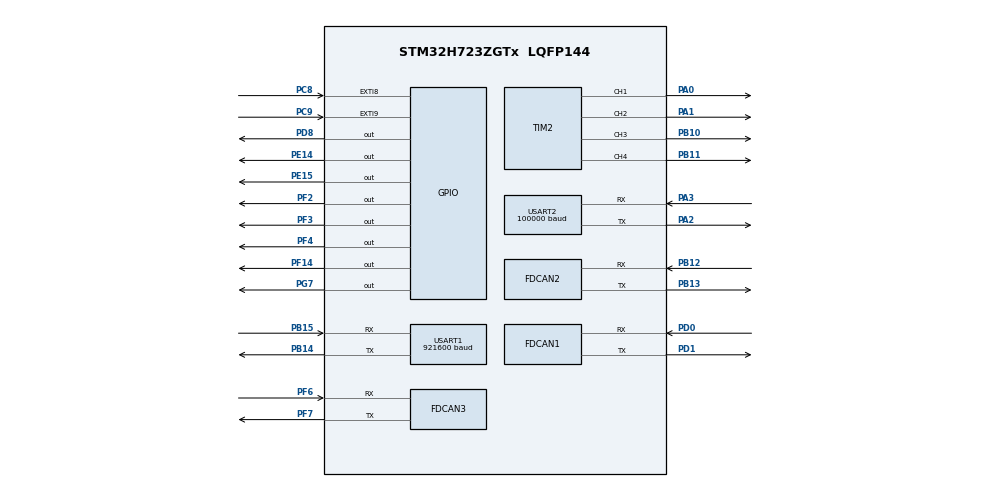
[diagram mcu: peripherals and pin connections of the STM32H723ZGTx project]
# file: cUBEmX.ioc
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CORTEX_M7.CPU_DCache=Disabled
CORTEX_M7.CPU_ICache=Disabled
CORTEX_M7.MPU_Control=__NULL
CORTEX_M7.default_mode_Activation=0
Dma.Request0=USART1_RX
Dma.Request1=USART1_TX
Dma.Request2=USART2_RX
Dma.USART1_RX.0.Direction=DMA_PERIPH_TO_MEMORY
Dma.USART1_RX.0.EventEnable=DISABLE
Dma.USART1_RX.0.FIFOMode=DMA_FIFOMODE_DISABLE
Dma.USART1_RX.0.Instance=DMA1_Stream1
Dma.USART1_RX.0.MemDataAlignment=DMA_MDATAALIGN_BYTE
Dma.USART1_RX.0.MemInc=DMA_MINC_ENABLE
Dma.USART1_RX.0.Mode=DMA_NORMAL
Dma.USART1_RX.0.PeriphDataAlignment=DMA_PDATAALIGN_BYTE
Dma.USART1_RX.0.PeriphInc=DMA_PINC_DISABLE
Dma.USART1_RX.0.Polarity=HAL_DMAMUX_REQ_GEN_RISING
Dma.USART1_RX.0.Priority=DMA_PRIORITY_LOW
Dma.USART1_RX.0.RequestNumber=1
Dma.USART1_RX.0.SignalID=NONE
Dma.USART1_RX.0.SyncEnable=DISABLE
Dma.USART1_RX.0.SyncPolarity=HAL_DMAMUX_SYNC_NO_EVENT
Dma.USART1_RX.0.SyncRequestNumber=1
Dma.USART1_RX.0.SyncSignalID=NONE
Dma.USART1_TX.1.Direction=DMA_MEMORY_TO_PERIPH
Dma.USART1_TX.1.EventEnable=DISABLE
Dma.USART1_TX.1.FIFOMode=DMA_FIFOMODE_DISABLE
Dma.USART1_TX.1.Instance=DMA1_Stream2
Dma.USART1_TX.1.MemDataAlignment=DMA_MDATAALIGN_BYTE
Dma.USART1_TX.1.MemInc=DMA_MINC_ENABLE
Dma.USART1_TX.1.Mode=DMA_NORMAL
Dma.USART1_TX.1.PeriphDataAlignment=DMA_PDATAALIGN_BYTE
Dma.USART1_TX.1.PeriphInc=DMA_PINC_DISABLE
Dma.USART1_TX.1.Polarity=HAL_DMAMUX_REQ_GEN_RISING
Dma.USART1_TX.1.Priority=DMA_PRIORITY_LOW
Dma.USART1_TX.1.RequestNumber=1
Dma.USART1_TX.1.SignalID=NONE
Dma.USART1_TX.1.SyncEnable=DISABLE
Dma.USART1_TX.1.SyncPolarity=HAL_DMAMUX_SYNC_NO_EVENT
Dma.USART1_TX.1.SyncRequestNumber=1
Dma.USART1_TX.1.SyncSignalID=NONE
Dma.USART2_RX.2.Direction=DMA_PERIPH_TO_MEMORY
Dma.USART2_RX.2.EventEnable=DISABLE
Dma.USART2_RX.2.FIFOMode=DMA_FIFOMODE_DISABLE
Dma.USART2_RX.2.Instance=DMA1_Stream0
Dma.USART2_RX.2.MemDataAlignment=DMA_MDATAALIGN_BYTE
Dma.USART2_RX.2.MemInc=DMA_MINC_ENABLE
Dma.USART2_RX.2.Mode=DMA_NORMAL
Dma.USART2_RX.2.PeriphDataAlignment=DMA_PDATAALIGN_BYTE
Dma.USART2_RX.2.PeriphInc=DMA_PINC_DISABLE
Dma.USART2_RX.2.Polarity=HAL_DMAMUX_REQ_GEN_RISING
Dma.USART2_RX.2.Priority=DMA_PRIORITY_MEDIUM
Dma.USART2_RX.2.RequestNumber=1
Dma.USART2_RX.2.SignalID=NONE
Dma.USART2_RX.2.SyncEnable=DISABLE
Dma.USART2_RX.2.SyncPolarity=HAL_DMAMUX_SYNC_NO_EVENT
Dma.USART2_RX.2.SyncRequestNumber=1
Dma.USART2_RX.2.SyncSignalID=NONE
FDCAN1.AutoRetransmission=ENABLE
FDCAN1.CalculateBaudRateNominal=1000000
FDCAN1.CalculateTimeBitNominal=1000
FDCAN1.CalculateTimeQuantumNominal=200.0
FDCAN1.ClockCalibrationCCU=DISABLE
FDCAN1.DataPrescaler=5
FDCAN1.DataTimeSeg1=2
FDCAN1.DataTimeSeg2=2
FDCAN1.NominalPrescaler=5
FDCAN1.RxFifo0ElmtsNbr=3
FDCAN1.StdFiltersNbr=1
FDCAN1.TxFifoQueueElmtsNbr=8
FDCAN1.TxFifoQueueMode=FDCAN_TX_FIFO_OPERATION
FDCAN2.AutoRetransmission=ENABLE
FDCAN2.CalculateBaudRateNominal=1000000
FDCAN2.CalculateTimeBitNominal=1000
FDCAN2.CalculateTimeQuantumNominal=200.0
FDCAN2.DataPrescaler=5
FDCAN2.DataTimeSeg1=2
FDCAN2.DataTimeSeg2=2
FDCAN2.MessageRAMOffset=796
FDCAN2.NominalPrescaler=5
FDCAN2.RxFifo0ElmtsNbr=3
FDCAN2.StdFiltersNbr=1
FDCAN2.TxFifoQueueElmtsNbr=8
FDCAN3.AutoRetransmission=ENABLE
FDCAN3.CalculateBaudRateNominal=1000000
FDCAN3.CalculateTimeBitNominal=1000
FDCAN3.CalculateTimeQuantumNominal=200.0
FDCAN3.DataPrescaler=5
FDCAN3.DataTimeSeg1=2
FDCAN3.DataTimeSeg2=2
FDCAN3.MessageRAMOffset=1592
FDCAN3.NominalPrescaler=5
FDCAN3.RxFifo0ElmtsNbr=3
FDCAN3.StdFiltersNbr=1
FDCAN3.TxFifoQueueElmtsNbr=8
Mcu.Family=STM32H7
Mcu.Name=STM32H723ZGTx
Mcu.Package=LQFP144
NVIC.DMA1_Stream0_IRQn=true\:0\:0\:false\:false\:true\:false\:true\:true
NVIC.DMA1_Stream1_IRQn=true\:0\:0\:false\:false\:true\:false\:true\:true
NVIC.DMA1_Stream2_IRQn=true\:0\:0\:false\:false\:true\:false\:true\:true
NVIC.FDCAN1_IT0_IRQn=true\:0\:0\:false\:false\:true\:true\:true\:true
NVIC.FDCAN2_IT0_IRQn=true\:0\:0\:false\:false\:true\:true\:true\:true
NVIC.FDCAN3_IT0_IRQn=true\:0\:0\:false\:false\:true\:true\:true\:true
NVIC.PriorityGroup=NVIC_PRIORITYGROUP_4
NVIC.USART1_IRQn=true\:0\:0\:false\:false\:true\:true\:true\:true
NVIC.USART2_IRQn=true\:0\:0\:false\:false\:true\:true\:true\:true
PA0.GPIO_Speed=GPIO_SPEED_FREQ_VERY_HIGH
PA0.Signal=S_TIM2_CH1_ETR
PA1.GPIO_Speed=GPIO_SPEED_FREQ_VERY_HIGH
PA1.Signal=S_TIM2_CH2
PA2.GPIO_Speed=GPIO_SPEED_FREQ_VERY_HIGH
PA2.Mode=Asynchronous
PA2.Signal=USART2_TX
PA3.GPIO_Speed=GPIO_SPEED_FREQ_VERY_HIGH
PA3.Mode=Asynchronous
PA3.Signal=USART2_RX
PB10.GPIO_Speed=GPIO_SPEED_FREQ_VERY_HIGH
PB10.Signal=S_TIM2_CH3
PB11.GPIO_Speed=GPIO_SPEED_FREQ_VERY_HIGH
PB11.Signal=S_TIM2_CH4
PB12.Mode=FDCAN_Activate
PB12.Signal=FDCAN2_RX
PB13.Mode=FDCAN_Activate
PB13.Signal=FDCAN2_TX
PB14.GPIO_Speed=GPIO_SPEED_FREQ_VERY_HIGH
PB14.Mode=Asynchronous
PB14.Signal=USART1_TX
PB15.GPIO_Speed=GPIO_SPEED_FREQ_VERY_HIGH
PB15.Mode=Asynchronous
PB15.Signal=USART1_RX
PC14-OSC32_IN.Mode=LSE-External-Oscillator
PC14-OSC32_IN.Signal=RCC_OSC32_IN
PC15-OSC32_OUT.Mode=LSE-External-Oscillator
PC15-OSC32_OUT.Signal=RCC_OSC32_OUT
PC8.GPIO_ModeDefaultEXTI=GPIO_MODE_IT_FALLING
PC8.GPIO_PuPd=GPIO_PULLUP
PC8.Signal=GPXTI8
PC9.GPIO_ModeDefaultEXTI=GPIO_MODE_IT_FALLING
PC9.GPIO_PuPd=GPIO_PULLUP
PC9.Signal=GPXTI9
PD0.GPIO_Speed=GPIO_SPEED_FREQ_VERY_HIGH
PD0.Mode=FDCAN_Activate
PD0.Signal=FDCAN1_RX
PD1.GPIO_Speed=GPIO_SPEED_FREQ_VERY_HIGH
PD1.Mode=FDCAN_Activate
PD1.Signal=FDCAN1_TX
PD8.GPIO_Speed=GPIO_SPEED_FREQ_VERY_HIGH
PD8.PinState=GPIO_PIN_RESET
PD8.Signal=GPIO_Output
PE14.GPIO_Speed=GPIO_SPEED_FREQ_VERY_HIGH
PE14.Signal=GPIO_Output
PE15.GPIO_Speed=GPIO_SPEED_FREQ_VERY_HIGH
PE15.Signal=GPIO_Output
PF14.GPIO_Speed=GPIO_SPEED_FREQ_VERY_HIGH
PF14.Signal=GPIO_Output
PF2.GPIO_Speed=GPIO_SPEED_FREQ_VERY_HIGH
PF2.Signal=GPIO_Output
PF3.GPIO_Speed=GPIO_SPEED_FREQ_VERY_HIGH
PF3.Signal=GPIO_Output
PF4.GPIO_Speed=GPIO_SPEED_FREQ_VERY_HIGH
PF4.Signal=GPIO_Output
PF6.Mode=FDCAN_Activate
PF6.Signal=FDCAN3_RX
PF7.Mode=FDCAN_Activate
PF7.Signal=FDCAN3_TX
PG7.GPIO_Speed=GPIO_SPEED_FREQ_VERY_HIGH
PG7.Signal=GPIO_Output
PH0-OSC_IN.Mode=HSE-External-Oscillator
PH0-OSC_IN.Signal=RCC_OSC_IN
PH1-OSC_OUT.Mode=HSE-External-Oscillator
PH1-OSC_OUT.Signal=RCC_OSC_OUT
ProjectManager.HeapSize=0x200
ProjectManager.StackSize=0x400
ProjectManager.TargetToolchain=MDK-ARM V5.32
RCC.ADCFreq_Value=129000000
RCC.APB1Freq_Value=120000000
RCC.APB2Freq_Value=120000000
RCC.APB3Freq_Value=120000000
RCC.APB4Freq_Value=120000000
RCC.CortexFreq_Value=480000000
RCC.D1PPRE=RCC_APB3_DIV2
RCC.D2PPRE1=RCC_APB1_DIV2
RCC.D2PPRE2=RCC_APB2_DIV2
RCC.D3PPRE=RCC_APB4_DIV2
RCC.DIVM1=4
RCC.DIVN1=30
RCC.DIVP1=1
RCC.DIVQ1=4
RCC.FDCANCLockSelection=RCC_FDCANCLKSOURCE_HSE
RCC.HCLKFreq_Value=240000000
RCC.HPRE=RCC_HCLK_DIV2
RCC.PLL2FRACN=0
RCC.PLL3FRACN=0
RCC.PLLFRACN=0
RCC.SYSCLKFreq_VALUE=480000000
RCC.SYSCLKSource=RCC_SYSCLKSOURCE_PLLCLK
RCC.USBFreq_Value=120000000
SH.S_TIM2_CH1_ETR.0=TIM2_CH1,PWM Generation1 CH1
SH.S_TIM2_CH2.0=TIM2_CH2,PWM Generation2 CH2
SH.S_TIM2_CH3.0=TIM2_CH3,PWM Generation3 CH3
SH.S_TIM2_CH4.0=TIM2_CH4,PWM Generation4 CH4
TIM2.Channel-PWM\ Generation1\ CH1=TIM_CHANNEL_1
TIM2.Channel-PWM\ Generation2\ CH2=TIM_CHANNEL_2
TIM2.Channel-PWM\ Generation3\ CH3=TIM_CHANNEL_3
TIM2.Channel-PWM\ Generation4\ CH4=TIM_CHANNEL_4
USART1.BaudRate=921600
USART1.VirtualMode-Asynchronous=VM_ASYNC
USART1.WordLength=WORDLENGTH_8B
USART2.BaudRate=100000
USART2.Mode=MODE_RX
USART2.Parity=PARITY_EVEN
USART2.VirtualMode-Asynchronous=VM_ASYNC
USART2.WordLength=WORDLENGTH_9B
board=custom

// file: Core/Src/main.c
/* USER CODE BEGIN Header */
/**
  ******************************************************************************
  * @file           : main.c
  * @brief          : Main program body
  ******************************************************************************
  * @attention
  *
  * Copyright (c) 2024 STMicroelectronics.
  * All rights reserved.
  *
  * This software is licensed under terms that can be found in the LICENSE file
  * in the root directory of this software component.
  * If no LICENSE file comes with this software, it is provided AS-IS.
  *
  ******************************************************************************
  */
/* USER CODE END Header */
#include "main.h"
#include "dma.h"
#include "fdcan.h"
#include "tim.h"
#include "usart.h"
#include "gpio.h"

/* USER CODE BEGIN Includes */
#include "board.h"
/* USER CODE END Includes */

void SystemClock_Config(void);

int main(void)
{

  /* MCU Configuration--------------------------------------------------------*/

  /* Reset of all peripherals, Initializes the Flash interface and the Systick. */
  HAL_Init();

  /* Configure the system clock */
  SystemClock_Config();

  /* Initialize all configured peripherals */
  MX_GPIO_Init();
  MX_DMA_Init();
  MX_TIM2_Init();
  MX_FDCAN1_Init();
  MX_USART1_UART_Init();
  MX_USART2_UART_Init();
  MX_FDCAN2_Init();
  MX_FDCAN3_Init();
  /* USER CODE BEGIN 2 */
	allInit();
  /* USER CODE END 2 */

  /* Infinite loop */
  while (1)
  {

  }
}

void SystemClock_Config(void)
{
  LL_FLASH_SetLatency(LL_FLASH_LATENCY_3);
  while(LL_FLASH_GetLatency()!= LL_FLASH_LATENCY_3)
  {
  }
  LL_PWR_ConfigSupply(LL_PWR_LDO_SUPPLY);
  LL_PWR_SetRegulVoltageScaling(LL_PWR_REGU_VOLTAGE_SCALE0);
  LL_RCC_HSE_Enable();

   /* Wait till HSE is ready */
  while(LL_RCC_HSE_IsReady() != 1)
  {

  }
  LL_RCC_HSI_Enable();

   /* Wait till HSI is ready */
  while(LL_RCC_HSI_IsReady() != 1)
  {

  }
  LL_RCC_HSI_SetCalibTrimming(64);
  LL_RCC_HSI_SetDivider(LL_RCC_HSI_DIV1);
  LL_RCC_PLL_SetSource(LL_RCC_PLLSOURCE_HSI);
  LL_RCC_PLL1P_Enable();
  LL_RCC_PLL1_SetVCOInputRange(LL_RCC_PLLINPUTRANGE_8_16);
  LL_RCC_PLL1_SetVCOOutputRange(LL_RCC_PLLVCORANGE_WIDE);
  LL_RCC_PLL1_SetM(4);
  LL_RCC_PLL1_SetN(30);
  LL_RCC_PLL1_SetP(1);
  LL_RCC_PLL1_SetQ(4);
  LL_RCC_PLL1_SetR(2);
  LL_RCC_PLL1_Enable();

   /* Wait till PLL is ready */
  while(LL_RCC_PLL1_IsReady() != 1)
  {
  }

   /* Intermediate AHB prescaler 2 when target frequency clock is higher than 80 MHz */
   LL_RCC_SetAHBPrescaler(LL_RCC_AHB_DIV_2);

  LL_RCC_SetSysClkSource(LL_RCC_SYS_CLKSOURCE_PLL1);

   /* Wait till System clock is ready */
  while(LL_RCC_GetSysClkSource() != LL_RCC_SYS_CLKSOURCE_STATUS_PLL1)
  {

  }
  LL_RCC_SetSysPrescaler(LL_RCC_SYSCLK_DIV_1);
  LL_RCC_SetAHBPrescaler(LL_RCC_AHB_DIV_2);
  LL_RCC_SetAPB1Prescaler(LL_RCC_APB1_DIV_2);
  LL_RCC_SetAPB2Prescaler(LL_RCC_APB2_DIV_2);
  LL_RCC_SetAPB3Prescaler(LL_RCC_APB3_DIV_2);
  LL_RCC_SetAPB4Prescaler(LL_RCC_APB4_DIV_2);
  LL_SetSystemCoreClock(480000000);

   /* Update the time base */
  if (HAL_InitTick (TICK_INT_PRIORITY) != HAL_OK)
  {
    Error_Handler();
  }
}

void Error_Handler(void)
{
  __disable_irq();
  while (1)
  {
  }
}
